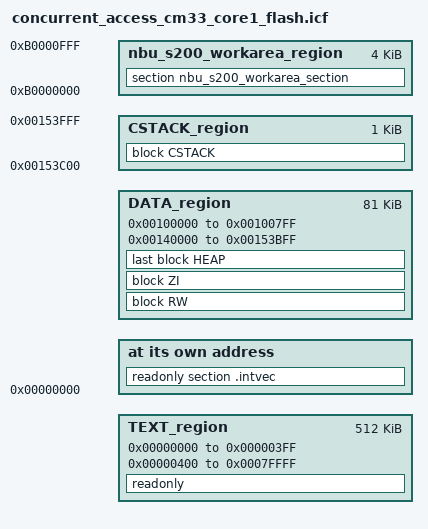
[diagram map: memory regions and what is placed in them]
/*
** ###################################################################
**     Processors:          MCXW727AMFTA_cm33_core1
**                          MCXW727CMFTA_cm33_core1
**                          MCXW727DMFTA_cm33_core1
**
**     Compiler:            IAR ANSI C/C++ Compiler for ARM
**     Reference manual:    Rev. 6, 05/22/2022
**     Version:             rev. 1.0, 2023-05-20
**     Build:               b240815
**
**     Abstract:
**         Linker file for the IAR ANSI C/C++ Compiler for ARM
**
**     Copyright 2016 Freescale Semiconductor, Inc.
**     Copyright 2016-2025 NXP
**     SPDX-License-Identifier: BSD-3-Clause
**
**     http:                 www.nxp.com
**     mail:                 support@nxp.com
**
** ###################################################################
*/


/* Stack and Heap Sizes */
if (isdefinedsymbol(__stack_size__)) {
  define symbol __size_cstack__        = __stack_size__;
} else {
  define symbol __size_cstack__        = 0x0400;
}

if (isdefinedsymbol(__heap_size__)) {
  define symbol __size_heap__          = __heap_size__;
} else {
  define symbol __size_heap__          = 0x0800;
}

/* We also reserve an S200-accessible workarea, into which we may place our in/out buffers
 * from the NBU core. We are careful not to overlap with the RPMSG section that is defined
 * in the Main core's linker at 0x489C8800 (address 0xB0008800 from NBU-core's perspective
 * due to shared memory address translation).
 */
define exported symbol m_nbu_s200_workarea_start = 0xB0000000;
define exported symbol m_nbu_s200_workarea_end   = 0xB0000FFF;

define symbol m_interrupts_start        = 0x00000000;
define symbol m_interrupts_end          = 0x000003FF;

define symbol m_text_start              = 0x00000400;
define symbol m_text_end                = 0x0007FFFF;

define symbol m_data0_start             = 0x00100000;
define symbol m_data0_end               = 0x001007FF;

define symbol m_data1_start             = 0x00140000;
define symbol m_data1_end               = 0x00153FFF - __size_cstack__;

define symbol m_stack_start             = 0x00154000 - __size_cstack__;
define symbol m_stack_end               = 0x00153FFF;

define memory mem with size = 4G;

define region TEXT_region              = mem:[from m_interrupts_start to m_interrupts_end]
                                       | mem:[from m_text_start to m_text_end];
define region DATA_region              = mem:[from m_data0_start to m_data0_end]
                                       | mem:[from m_data1_start to m_data1_end];
define region CSTACK_region            = mem:[from m_stack_start to m_stack_end];
define region nbu_s200_workarea_region = mem:[from m_nbu_s200_workarea_start to m_nbu_s200_workarea_end];


define block CSTACK    with alignment = 8, size = __size_cstack__   { };
define block HEAP      with alignment = 8, size = __size_heap__     { };
define block RW        { readwrite };
define block ZI        { zi };

initialize by copy { readwrite, section .textrw };

if (isdefinedsymbol(__USE_DLIB_PERTHREAD))
{
  /* Required in a multi-threaded application */
  initialize by copy with packing = none { section __DLIB_PERTHREAD };
}

do not initialize  { section .noinit };

place at address mem: m_interrupts_start    { readonly section .intvec };
place in TEXT_region                        { readonly };
place in DATA_region                        { block RW };
place in DATA_region                        { block ZI };
place in DATA_region                        { last block HEAP };
place in CSTACK_region                      { block CSTACK };
place in nbu_s200_workarea_region           { section nbu_s200_workarea_section };
